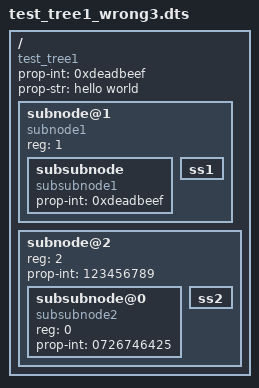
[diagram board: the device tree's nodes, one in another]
/dts-v1/;

/memreserve/ 0xdeadbeef00000000 0x100000;
/memreserve/ 123456789 010000;

/ {
	compatible = "test_tree1";
	prop-int = <0xdeadbeef>;
	prop-str = "hello world";
	#address-cells = <1>;
	#size-cells = <0>;

	subnode@1 {
		compatible = "subnode1";
		reg = <1>;

		subsubnode {
			compatible = "subsubnode1", "subsubnode";
			prop-int = <0xdeadbeef>;
		};

		ss1 {
		};
	};

	subnode@2 {
		reg = <2>;
		linux,phandle = <0x2000>;
		prop-int = <123456789>;
		#address-cells = <1>;
		#size-cells = <0>;

		subsubnode@0 {
			reg = <0>;
			phandle = <0x2001>;
			compatible = "subsubnode2", "subsubnode";
			prop-int = <0726746425>;
		};

		ss2 {
		};
	};
};
